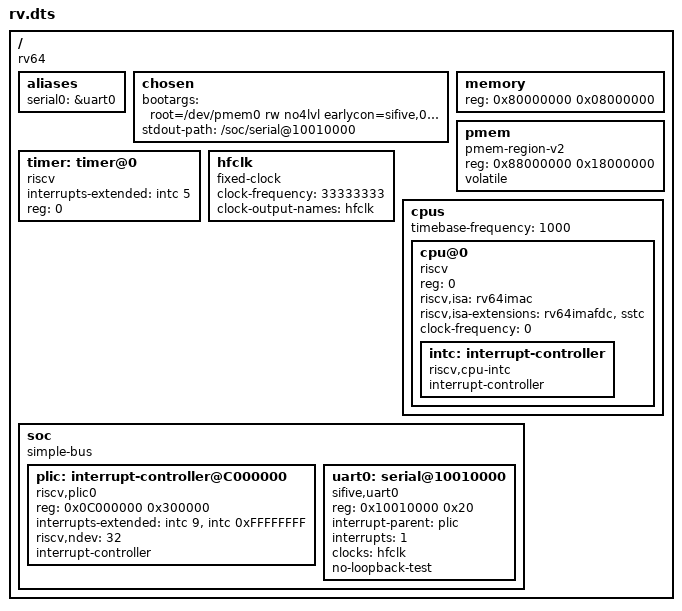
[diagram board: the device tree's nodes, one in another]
/dts-v1/;

/ {
	#address-cells = <1>;
	#size-cells = <1>;
	compatible = "rv64";

	aliases {
		serial0 = &uart0;
	};

	chosen {
		bootargs = "root=/dev/pmem0 rw no4lvl earlycon=sifive,0x10010000 console=ttySIF0";
		stdout-path = "/soc/serial@10010000";
	};

	memory {
		device_type = "memory";
		reg = <0x80000000 0x08000000>; // do not change memory base address 0x80000000
	};

	pmem {
		compatible = "pmem-region-v2";
		reg = <0x88000000 0x18000000>;
		volatile;
	};

	timer: timer@0 {
		#clock-cells = <0>;
		compatible = "riscv", "riscv,timer";
		interrupts-extended = <&intc 5>;
		reg = <0>;
	};

	hfclk: hfclk {
		#clock-cells = <0>;
		compatible = "fixed-clock";
		clock-frequency = <33333333>;
		clock-output-names = "hfclk";
	};

	cpus {
		#address-cells = <1>;
		#size-cells = <0>;
		timebase-frequency = <1000>;
		cpu@0 {
			device_type = "cpu";
			reg = <0>;
			status = "okay";
			compatible = "riscv";
			riscv,isa = "rv64imac";
			riscv,isa-extensions = "rv64imafdc", "sstc";
			clock-frequency = <0>;

			intc: interrupt-controller {
				#interrupt-cells = <1>;
				compatible = "riscv,cpu-intc";
				interrupt-controller;
			};
		};
	};

	soc {
		#address-cells = <1>;
		#size-cells = <1>;
		compatible = "simple-bus";
		ranges;

		plic: interrupt-controller@C000000 {
			#address-cells = <0>;
			#interrupt-cells = <1>;
			#size-cells = <1>;
			compatible = "riscv,plic0";
			reg = <0x0C000000 0x300000>;
			interrupts-extended = <&intc 9 &intc 0xFFFFFFFF>;
			riscv,ndev = <32>;
			interrupt-controller;
		};

		uart0: serial@10010000 {
			compatible = "sifive,uart0";
			reg = <0x10010000 0x20>;
			interrupt-parent = <&plic>;
			interrupts = <1>;
			clocks = <&hfclk>;
			no-loopback-test;
		};
	};
};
